VERSION ""

NS_ :

BS_:

BU_: DevPC MCU

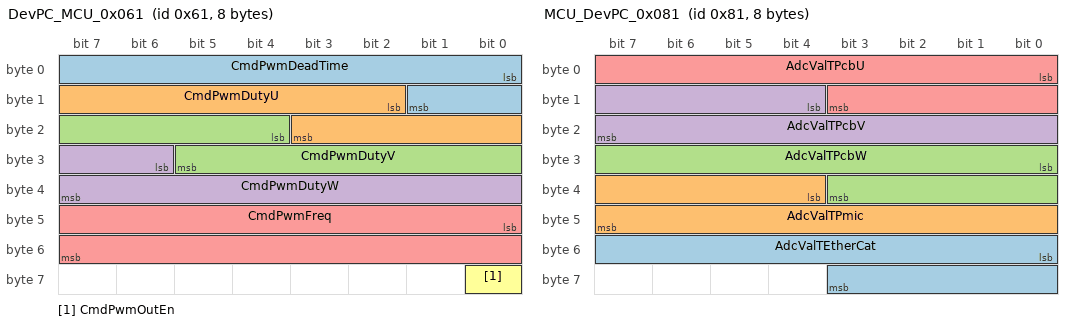
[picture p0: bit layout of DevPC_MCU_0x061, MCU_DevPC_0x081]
BO_ 97 DevPC_MCU_0x061: 8 DevPC
 SG_ CmdPwmDeadTime : 0|10@1+ (0.01,0) [0|10.23] "us" MCU
 SG_ CmdPwmDutyU : 10|10@1+ (0.1,0) [0|102.3] "%" MCU
 SG_ CmdPwmDutyV : 20|10@1+ (0.1,0) [0|102.3] "%" MCU
 SG_ CmdPwmDutyW : 30|10@1+ (0.1,0) [0|102.3] "%" MCU
 SG_ CmdPwmFreq : 40|16@1+ (1.0,0) [0|65535] "Hz" MCU
 SG_ CmdPwmOutEn : 56|1@1+ (1.0,0) [0|1] "" MCU

BO_ 129 MCU_DevPC_0x081: 8 MCU
 SG_ AdcValTEtherCat : 48|12@1+ (1.0,0) [0|4095] "" DevPC
 SG_ AdcValTPmic : 36|12@1+ (1.0,0) [0|4095] "" DevPC
 SG_ AdcValTPcbW : 24|12@1+ (1.0,0) [0|4095] "" DevPC
 SG_ AdcValTPcbV : 12|12@1+ (1.0,0) [0|4095] "" DevPC
 SG_ AdcValTPcbU : 0|12@1+ (1.0,0) [0|4095] "" DevPC

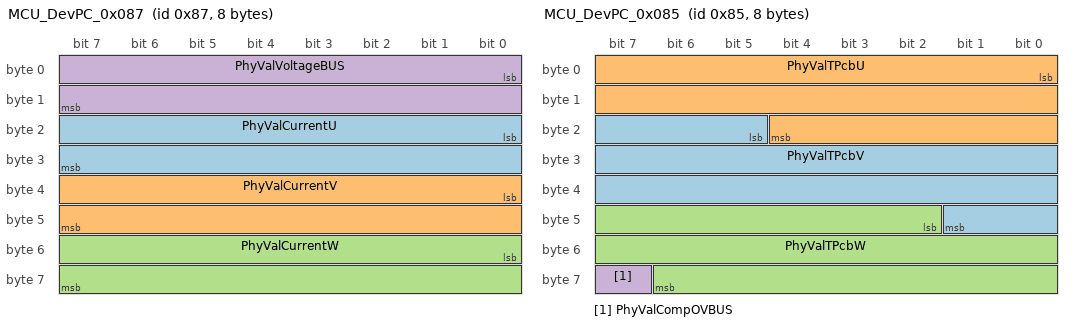
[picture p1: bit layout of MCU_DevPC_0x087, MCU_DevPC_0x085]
BO_ 135 MCU_DevPC_0x087: 8 MCU
 SG_ PhyValCurrentU : 16|16@1+ (0.01,-300) [-300|355.35] "A" DevPC
 SG_ PhyValCurrentV : 32|16@1+ (0.01,-300) [-300|355.35] "A" DevPC
 SG_ PhyValCurrentW : 48|16@1+ (0.01,-300) [-300|355.35] "A" DevPC
 SG_ PhyValVoltageBUS : 0|16@1+ (0.01,0) [0|655.35] "V" DevPC

BO_ 133 MCU_DevPC_0x085: 8 MCU
 SG_ PhyValTPcbV : 21|21@1+ (0.1,0) [0|209715.1] "ohm" DevPC
 SG_ PhyValTPcbU : 0|21@1+ (0.1,0) [0|209715.1] "ohm" DevPC
 SG_ PhyValTPcbW : 42|21@1+ (0.1,0) [0|209715.1] "ohm" DevPC
 SG_ PhyValCompOVBUS : 63|1@1+ (1.0,0) [0|1] "" DevPC

BA_DEF_ SG_  "GenSigStartValue" HEX 0 0;
BA_DEF_ BO_  "GenMsgCycleTime" INT 0 65535;
BA_DEF_  "BusType" STRING ;
BA_DEF_DEF_  "GenSigStartValue" 0;
BA_DEF_DEF_  "GenMsgCycleTime" 0;
BA_DEF_DEF_  "BusType" "CAN";

BA_ "GenMsgCycleTime" BO_ 97 100;
BA_ "GenMsgCycleTime" BO_ 129 50;
BA_ "GenMsgCycleTime" BO_ 135 20;
BA_ "GenMsgCycleTime" BO_ 133 500;

BA_ "GenSigStartValue" SG_ 97 CmdPwmDeadTime 1;
BA_ "GenSigStartValue" SG_ 97 CmdPwmDutyU 50;
BA_ "GenSigStartValue" SG_ 97 CmdPwmDutyV 50;
BA_ "GenSigStartValue" SG_ 97 CmdPwmDutyW 50;
BA_ "GenSigStartValue" SG_ 97 CmdPwmFreq 10000;
